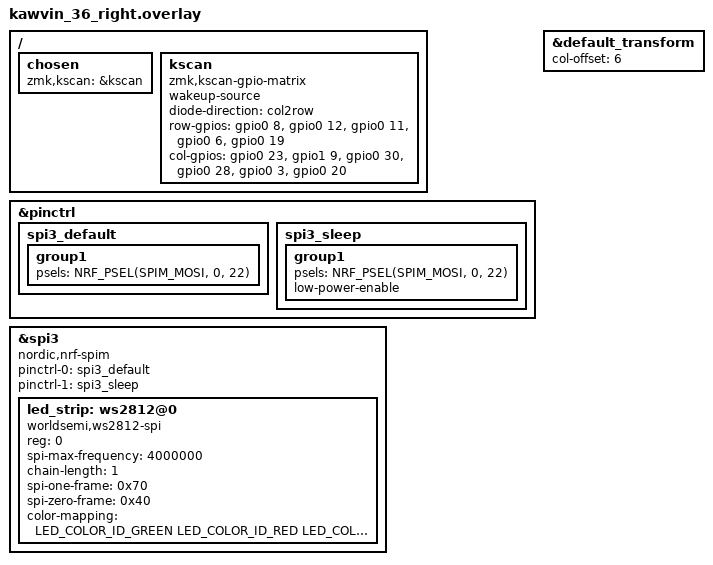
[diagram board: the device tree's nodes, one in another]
/*
 * Copyright (c) 2023 The ZMK Contributors
 *
 * SPDX-License-Identifier: MIT
 */

#include "kawvin_36.dtsi"
#include <dt-bindings/led/led.h>

&pinctrl {
    spi3_default: spi3_default {
        group1 {
            psels = <NRF_PSEL(SPIM_MOSI, 0, 22)>;
        };
    };

    spi3_sleep: spi3_sleep {
        group1 {
            psels = <NRF_PSEL(SPIM_MOSI, 0, 22)>;
            low-power-enable;
        };
    };
};

&spi3 {
    compatible = "nordic,nrf-spim";
    status = "okay";

    pinctrl-0 = <&spi3_default>;
    pinctrl-1 = <&spi3_sleep>;
    pinctrl-names = "default", "sleep";

    led_strip: ws2812@0 {
        compatible = "worldsemi,ws2812-spi";

        /* SPI */
        reg = <0>; /* ignored, but necessary for SPI bindings */
        spi-max-frequency = <4000000>;

        /* WS2812 */
        chain-length = <1>; /* arbitrary; change at will */
        spi-one-frame = <0x70>;
        spi-zero-frame = <0x40>;
        color-mapping = <LED_COLOR_ID_GREEN LED_COLOR_ID_RED LED_COLOR_ID_BLUE>;
    };
};

/ {
    chosen {
        zmk,kscan = &kscan;
    };

    kscan: kscan {
        compatible = "zmk,kscan-gpio-matrix";
        wakeup-source;

        diode-direction = "col2row";

        row-gpios
            = <&gpio0  8 (GPIO_PULL_DOWN | GPIO_ACTIVE_HIGH)>
            , <&gpio0 12 (GPIO_PULL_DOWN | GPIO_ACTIVE_HIGH)>
            , <&gpio0 11 (GPIO_PULL_DOWN | GPIO_ACTIVE_HIGH)>
            , <&gpio0  6 (GPIO_PULL_DOWN | GPIO_ACTIVE_HIGH)>
            , <&gpio0 19 (GPIO_PULL_DOWN | GPIO_ACTIVE_HIGH)>
            ;

        col-gpios
            = <&gpio0 23 GPIO_ACTIVE_HIGH>
            , <&gpio1  9 GPIO_ACTIVE_HIGH>
            , <&gpio0 30 GPIO_ACTIVE_HIGH>
            , <&gpio0 28 GPIO_ACTIVE_HIGH>
            , <&gpio0  3 GPIO_ACTIVE_HIGH>
            , <&gpio0 20 GPIO_ACTIVE_HIGH>
            ;
    };
};

&default_transform {
    col-offset = <6>;
};

